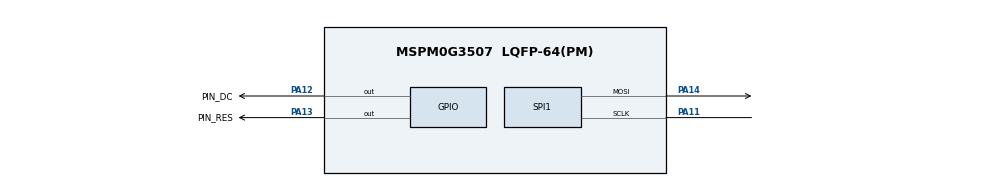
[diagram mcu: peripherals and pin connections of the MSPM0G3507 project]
/**
 * These arguments were used when this file was generated. They will be automatically applied on subsequent loads
 * via the GUI or CLI. Run CLI with '--help' for additional information on how to override these arguments.
 * @cliArgs --device "MSPM0G350X" --part "Default" --package "LQFP-64(PM)" --product "mspm0_sdk@2.05.01.01"
 * @v2CliArgs --device "MSPM0G3507" --package "LQFP-64(PM)" --product "mspm0_sdk@2.05.01.01"
 * @versions {"tool":"1.24.0+4110"}
 */

/**
 * Import the modules used in this configuration.
 */
const GPIO   = scripting.addModule("/ti/driverlib/GPIO", {}, false);
const GPIO1  = GPIO.addInstance();
const SPI    = scripting.addModule("/ti/driverlib/SPI", {}, false);
const SPI1   = SPI.addInstance();
const SYSCTL = scripting.addModule("/ti/driverlib/SYSCTL");

/**
 * Write custom configuration values to the imported modules.
 */
GPIO1.$name                         = "GPIO_OLED";
GPIO1.associatedPins.create(2);
GPIO1.associatedPins[0].$name       = "PIN_DC";
GPIO1.associatedPins[0].pin.$assign = "PA12";
GPIO1.associatedPins[1].$name       = "PIN_RES";
GPIO1.associatedPins[1].pin.$assign = "PA13";

const Board = scripting.addModule("/ti/driverlib/Board", {}, false);

SPI1.$name                          = "SPI_0";
SPI1.frameFormat                    = "MOTO3";
SPI1.polarity                       = "1";
SPI1.phase                          = "1";
SPI1.direction                      = "PICO";
SPI1.enabledInterrupts              = ["DMA_DONE_TX","TX_EMPTY"];
SPI1.enabledDMAEvent2Triggers       = "DL_SPI_DMA_INTERRUPT_TX";
SPI1.sclkPinConfig.$name            = "ti_driverlib_gpio_GPIOPinGeneric0";
SPI1.mosiPinConfig.$name            = "ti_driverlib_gpio_GPIOPinGeneric1";
SPI1.peripheral.$assign             = "SPI0";
SPI1.peripheral.sclkPin.$assign     = "PA11";
SPI1.peripheral.mosiPin.$assign     = "PA14";
SPI1.DMA_CHANNEL_EVENT2.$name       = "DMA_CH0";
SPI1.DMA_CHANNEL_EVENT2.srcLength   = "BYTE";
SPI1.DMA_CHANNEL_EVENT2.dstLength   = "BYTE";
SPI1.DMA_CHANNEL_EVENT2.addressMode = "b2f";

SYSCTL.forceDefaultClkConfig = true;

/**
 * Pinmux solution for unlocked pins/peripherals. This ensures that minor changes to the automatic solver in a future
 * version of the tool will not impact the pinmux you originally saw.  These lines can be completely deleted in order to
 * re-solve from scratch.
 */
Board.peripheral.$suggestSolution                   = "DEBUGSS";
Board.peripheral.swclkPin.$suggestSolution          = "PA20";
Board.peripheral.swdioPin.$suggestSolution          = "PA19";
SPI1.DMA_CHANNEL_EVENT2.peripheral.$suggestSolution = "DMA_CH0";
SYSCTL.peripheral.$suggestSolution                  = "SYSCTL";
